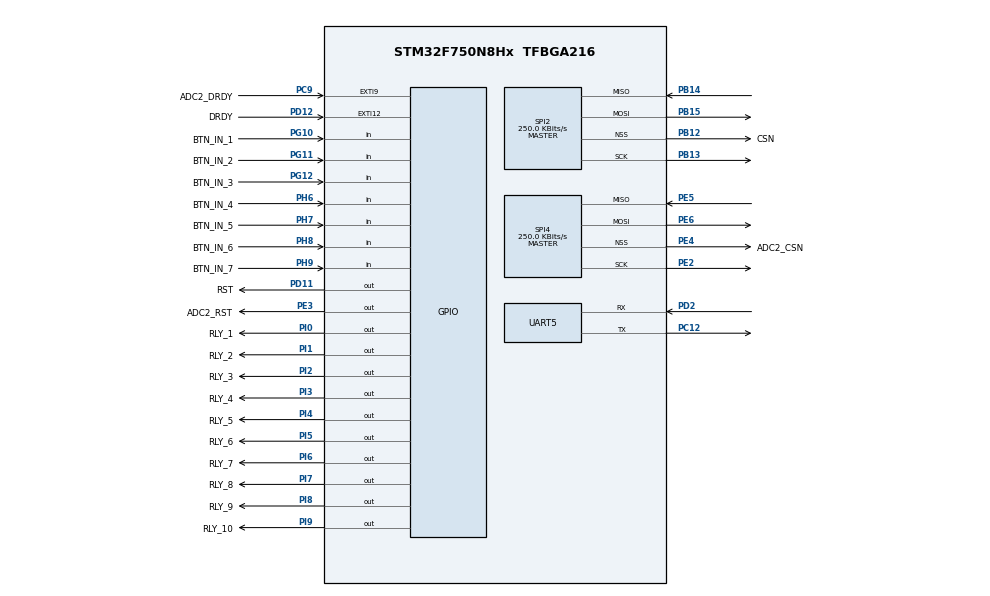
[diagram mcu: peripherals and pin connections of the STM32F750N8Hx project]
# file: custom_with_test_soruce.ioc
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FREERTOS.BinarySemaphores01=pradeep,Dynamic,NULL
FREERTOS.Tasks01=defaultTask,24,128,StartDefaultTask,Default,NULL,Dynamic,NULL,NULL;myTask02,24,128,StartTask02,Default,NULL,Dynamic,NULL,NULL
FREERTOS.configCHECK_FOR_STACK_OVERFLOW=2
FREERTOS.configUSE_IDLE_HOOK=1
FREERTOS.configUSE_MALLOC_FAILED_HOOK=1
FREERTOS.configUSE_NEWLIB_REENTRANT=1
FREERTOS.configUSE_TICK_HOOK=1
Mcu.Family=STM32F7
Mcu.Name=STM32F750N8Hx
Mcu.Package=TFBGA216
NVIC.EXTI15_10_IRQn=true\:5\:0\:false\:false\:true\:true\:true\:true\:true
NVIC.EXTI9_5_IRQn=true\:5\:0\:false\:false\:true\:true\:true\:true\:true
NVIC.PriorityGroup=NVIC_PRIORITYGROUP_4
NVIC.TIM1_UP_TIM10_IRQn=true\:5\:0\:false\:false\:true\:true\:true\:true\:true
NVIC.TIM7_IRQn=true\:15\:0\:false\:false\:true\:false\:false\:true\:true
NVIC.TimeBase=TIM7_IRQn
NVIC.TimeBaseIP=TIM7
PB12.GPIO_Label=CSN
PB12.Mode=NSS_Signal_Hard_Output
PB12.Signal=SPI2_NSS
PB13.Mode=Full_Duplex_Master
PB13.Signal=SPI2_SCK
PB14.Mode=Full_Duplex_Master
PB14.Signal=SPI2_MISO
PB15.Mode=Full_Duplex_Master
PB15.Signal=SPI2_MOSI
PC12.Mode=Asynchronous
PC12.Signal=UART5_TX
PC9.GPIO_Label=ADC2_DRDY
PC9.GPIO_ModeDefaultEXTI=GPIO_MODE_IT_FALLING
PC9.GPIO_PuPd=GPIO_PULLUP
PC9.Signal=GPXTI9
PD11.GPIO_Label=RST
PD11.Signal=GPIO_Output
PD12.GPIO_Label=DRDY
PD12.GPIO_ModeDefaultEXTI=GPIO_MODE_IT_FALLING
PD12.GPIO_PuPd=GPIO_PULLUP
PD12.Signal=GPXTI12
PD2.Mode=Asynchronous
PD2.Signal=UART5_RX
PE2.Mode=Full_Duplex_Master
PE2.Signal=SPI4_SCK
PE3.GPIO_Label=ADC2_RST
PE3.Signal=GPIO_Output
PE4.GPIO_Label=ADC2_CSN
PE4.Mode=NSS_Signal_Hard_Output
PE4.Signal=SPI4_NSS
PE5.Mode=Full_Duplex_Master
PE5.Signal=SPI4_MISO
PE6.Mode=Full_Duplex_Master
PE6.Signal=SPI4_MOSI
PG10.GPIO_Label=BTN_IN_1
PG10.Signal=GPIO_Input
PG11.GPIO_Label=BTN_IN_2
PG11.Signal=GPIO_Input
PG12.GPIO_Label=BTN_IN_3
PG12.Signal=GPIO_Input
PH0/OSC_IN.Mode=HSE-External-Oscillator
PH0/OSC_IN.Signal=RCC_OSC_IN
PH1/OSC_OUT.Mode=HSE-External-Oscillator
PH1/OSC_OUT.Signal=RCC_OSC_OUT
PH6.GPIO_Label=BTN_IN_4
PH6.Signal=GPIO_Input
PH7.GPIO_Label=BTN_IN_5
PH7.Signal=GPIO_Input
PH8.GPIO_Label=BTN_IN_6
PH8.Signal=GPIO_Input
PH9.GPIO_Label=BTN_IN_7
PH9.Signal=GPIO_Input
PI0.GPIO_Label=RLY_1
PI0.Signal=GPIO_Output
PI1.GPIO_Label=RLY_2
PI1.Signal=GPIO_Output
PI2.GPIO_Label=RLY_3
PI2.Signal=GPIO_Output
PI3.GPIO_Label=RLY_4
PI3.Signal=GPIO_Output
PI4.GPIO_Label=RLY_5
PI4.Signal=GPIO_Output
PI5.GPIO_Label=RLY_6
PI5.Signal=GPIO_Output
PI6.GPIO_Label=RLY_7
PI6.Signal=GPIO_Output
PI7.GPIO_Label=RLY_8
PI7.Signal=GPIO_Output
PI8.GPIO_Label=RLY_9
PI8.Signal=GPIO_Output
PI9.GPIO_Label=RLY_10
PI9.Signal=GPIO_Output
ProjectManager.HeapSize=0x200
ProjectManager.StackSize=0x400
ProjectManager.TargetToolchain=STM32CubeIDE
RCC.HSE_VALUE=25000000
RCC.HSI_VALUE=16000000
RCC.LSE_VALUE=32768
RCC.USBFreq_Value=96000000
RCC.VCOOutputFreq_Value=192000000
SPI2.BaudRatePrescaler=SPI_BAUDRATEPRESCALER_64
SPI2.CLKPhase=SPI_PHASE_2EDGE
SPI2.CalculateBaudRate=250.0 KBits/s
SPI2.DataSize=SPI_DATASIZE_8BIT
SPI2.Direction=SPI_DIRECTION_2LINES
SPI2.Mode=SPI_MODE_MASTER
SPI2.VirtualNSS=VM_NSSHARD
SPI2.VirtualType=VM_MASTER
SPI4.BaudRatePrescaler=SPI_BAUDRATEPRESCALER_64
SPI4.CLKPhase=SPI_PHASE_2EDGE
SPI4.CalculateBaudRate=250.0 KBits/s
SPI4.DataSize=SPI_DATASIZE_8BIT
SPI4.Direction=SPI_DIRECTION_2LINES
SPI4.Mode=SPI_MODE_MASTER
SPI4.VirtualNSS=VM_NSSHARD
SPI4.VirtualType=VM_MASTER
TIM1.Prescaler=36000-1
TIM12.Prescaler=16-1
TIM9.Prescaler=16-1
VP_FREERTOS_VS_CMSIS_V2.Mode=CMSIS_V2
VP_SYS_VS_tim7.Mode=TIM7
VP_TIM12_VS_ClockSourceINT.Mode=Internal
VP_TIM1_VS_ClockSourceINT.Mode=Internal
VP_TIM9_VS_ClockSourceINT.Mode=Internal
board=custom

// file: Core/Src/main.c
/* USER CODE BEGIN Header */
/**
  ******************************************************************************
  * @file           : main.c
  * @brief          : Main program body
  ******************************************************************************
  * @attention
  *
  * Copyright (c) 2022 STMicroelectronics.
  * All rights reserved.
  *
  * This software is licensed under terms that can be found in the LICENSE file
  * in the root directory of this software component.
  * If no LICENSE file comes with this software, it is provided AS-IS.
  *
  ******************************************************************************
  */
/* USER CODE END Header */
#include "main.h"
#include "cmsis_os.h"
#include "retarget.h"
#include "ADS1256.h"
#include "ADC_CUSTOM.h"
#include "spi.h"
#include "gpio.h"
#include "tim.h"
#include "stdio.h"
#include "string.h"

extern ads125x_channel_info_t ads125x_channel_info;
extern ads125x_conf_t ads125x_conf;
//static uint8_t is_adc_drdy,is_timer_expired;

extern ADC_CHANNEL_INFO_T ADC_CHANNEL_INFO;
extern ADC_CONFIG_T ADC_CONFIG;
//static uint8_t IS_ADC_DRDY,IS_TIMER_EXPIRED;

UART_HandleTypeDef huart5;

/* Definitions for defaultTask */
osThreadId_t defaultTaskHandle;
const osThreadAttr_t defaultTask_attributes = {
  .name = "defaultTask",
  .stack_size = 128 * 4,
  .priority = (osPriority_t) osPriorityNormal,
};
/* Definitions for myTask02 */
osThreadId_t myTask02Handle;
const osThreadAttr_t myTask02_attributes = {
  .name = "myTask02",
  .stack_size = 128 * 4,
  .priority = (osPriority_t) osPriorityNormal,
};
/* Definitions for pradeep */
osSemaphoreId_t pradeepHandle;
const osSemaphoreAttr_t pradeep_attributes = {
  .name = "pradeep"
};

void SystemClock_Config(void);
static void MX_UART5_Init(void);
void StartDefaultTask(void *argument);
void StartTask02(void *argument);

int main(void)
{

  /* MCU Configuration--------------------------------------------------------*/

  /* Reset of all peripherals, Initializes the Flash interface and the Systick. */
  HAL_Init();

  /* Configure the system clock */
  SystemClock_Config();

  /* Initialize all configured peripherals */
  MX_GPIO_Init();
  MX_SPI2_Init();
  MX_UART5_Init();
  MX_SPI4_Init();
  MX_TIM12_Init();
  MX_TIM9_Init();
  MX_TIM1_Init();
  RetargetInit(&huart5);
  hal_tim1_rpti_init(ads125x_conf.report_interval_ms);
  uint8_t status = ads1256_init();

  if(status == 1)
  {
	  printf("initialization was done for off_board\r\n");
  }
  else
  {
	  printf("initialization was not done for off_board\r\n");
  }

  status = ADC_INIT();
  if(status == 1)
  {
	  printf("initialization was done for on_board\r\n");
  }
  else
  {
	  printf("initialization was not done for on_board\r\n");
  }

  /* Init scheduler */
  osKernelInitialize();

  /* Create the semaphores(s) */
  /* creation of pradeep */
  pradeepHandle = osSemaphoreNew(1, 1, &pradeep_attributes);

  /* Create the thread(s) */
  /* creation of defaultTask */
  defaultTaskHandle = osThreadNew(StartDefaultTask, NULL, &defaultTask_attributes);

  /* creation of myTask02 */
  myTask02Handle = osThreadNew(StartTask02, NULL, &myTask02_attributes);

  /* Start scheduler */
  osKernelStart();

  /* We should never get here as control is now taken by the scheduler */
  /* Infinite loop */
  while (1)
  {

  }
}

void SystemClock_Config(void)
{
  RCC_OscInitTypeDef RCC_OscInitStruct = {0};
  RCC_ClkInitTypeDef RCC_ClkInitStruct = {0};

  /** Configure the main internal regulator output voltage
  */
  __HAL_RCC_PWR_CLK_ENABLE();
  __HAL_PWR_VOLTAGESCALING_CONFIG(PWR_REGULATOR_VOLTAGE_SCALE3);

  /** Initializes the RCC Oscillators according to the specified parameters
  * in the RCC_OscInitTypeDef structure.
  */
  RCC_OscInitStruct.OscillatorType = RCC_OSCILLATORTYPE_HSI;
  RCC_OscInitStruct.HSIState = RCC_HSI_ON;
  RCC_OscInitStruct.HSICalibrationValue = RCC_HSICALIBRATION_DEFAULT;
  RCC_OscInitStruct.PLL.PLLState = RCC_PLL_NONE;
  if (HAL_RCC_OscConfig(&RCC_OscInitStruct) != HAL_OK)
  {
    Error_Handler();
  }

  /** Initializes the CPU, AHB and APB buses clocks
  */
  RCC_ClkInitStruct.ClockType = RCC_CLOCKTYPE_HCLK|RCC_CLOCKTYPE_SYSCLK
                              |RCC_CLOCKTYPE_PCLK1|RCC_CLOCKTYPE_PCLK2;
  RCC_ClkInitStruct.SYSCLKSource = RCC_SYSCLKSOURCE_HSI;
  RCC_ClkInitStruct.AHBCLKDivider = RCC_SYSCLK_DIV1;
  RCC_ClkInitStruct.APB1CLKDivider = RCC_HCLK_DIV1;
  RCC_ClkInitStruct.APB2CLKDivider = RCC_HCLK_DIV1;

  if (HAL_RCC_ClockConfig(&RCC_ClkInitStruct, FLASH_LATENCY_0) != HAL_OK)
  {
    Error_Handler();
  }
}

static void MX_UART5_Init(void)
{

  huart5.Instance = UART5;
  huart5.Init.BaudRate = 115200;
  huart5.Init.WordLength = UART_WORDLENGTH_8B;
  huart5.Init.StopBits = UART_STOPBITS_1;
  huart5.Init.Parity = UART_PARITY_NONE;
  huart5.Init.Mode = UART_MODE_TX_RX;
  huart5.Init.HwFlowCtl = UART_HWCONTROL_NONE;
  huart5.Init.OverSampling = UART_OVERSAMPLING_16;
  huart5.Init.OneBitSampling = UART_ONE_BIT_SAMPLE_DISABLE;
  huart5.AdvancedInit.AdvFeatureInit = UART_ADVFEATURE_NO_INIT;
  if (HAL_UART_Init(&huart5) != HAL_OK)
  {
    Error_Handler();
  }

}

void StartDefaultTask(void *argument)
{
  /* USER CODE BEGIN 5 */
  /* Infinite loop */
  for(;;)
  {
//	  do
//	  {
//		  //	  	  IS_ADC_DRDY = 0;
//		  		  __disable_irq();
//		  		  ADC_DRDY_ISR();
//		  		  __enable_irq();
//	  }
//	  while(HAL_GPIO_ReadPin(DRDY_GPIO_Port, DRDY_Pin) == 0);

if(HAL_GPIO_ReadPin(DRDY_GPIO_Port, DRDY_Pin) == 0)
{

	osSemaphoreAcquire(pradeepHandle, osWaitForever);
	__disable_irq();
	ADC_DRDY_ISR();
	__enable_irq();
	 osSemaphoreRelease(pradeepHandle);
}
else
{

}

//  	  ADS1256_GetAll(ADC_Value);
//  	  float mV = (ADC_Value[0]*2*2.5)/(32 * 8388607)*1000;
//  	  printf("ADC_Value:%lf mvolts\t",mV);
//  	  float psi, res = 0.00005;
//  	  int psi_int = (0.0629*mV - 0.1306)/res;  //converting milli volts into psi
//  	  psi = psi_int*res;
//  	  printf("pis:%f\r\n",psi);

  }
  /* USER CODE END 5 */
}

void StartTask02(void *argument)
{
  /* USER CODE BEGIN StartTask02 */
  /* Infinite loop */
  for(;;)
  {

//    printf("second_task\r\n");

//    osDelay(2000);
//	    do
//		  {
//			  //is_adc_drdy = 0;
//			  __disable_irq();
//			  ads1256_drdy_isr();
//			  __enable_irq();
//
//		  }
//		  while(HAL_GPIO_ReadPin(ADC2_DRDY_GPIO_Port, ADC2_DRDY_Pin) == 0);
//	    osThreadSuspend(myTask02Handle);

	    if(HAL_GPIO_ReadPin(ADC2_DRDY_GPIO_Port, ADC2_DRDY_Pin) == 0)
	    {
	    	osSemaphoreAcquire(pradeepHandle, osWaitForever);
	    	__disable_irq();
	    	ads1256_drdy_isr();
	    	__enable_irq();
	    	 osSemaphoreRelease(pradeepHandle);
	    }
	    else
	    {

	    }

	//	  osSemaphoreAcquire(pradeepHandle, osWaitForever);
	//	  printf("acquire\r\n");
	//	  printf("release\r\n");
	//	  osSemaphoreRelease(pradeepHandle);

  }
  /* USER CODE END StartTask02 */
}

void HAL_TIM_PeriodElapsedCallback(TIM_HandleTypeDef *htim)
{
  if (htim->Instance == TIM7) {
    HAL_IncTick();
  }
}

void Error_Handler(void)
{
  __disable_irq();
  while (1)
  {
  }
}

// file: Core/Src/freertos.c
/* USER CODE BEGIN Header */
/**
  ******************************************************************************
  * File Name          : freertos.c
  * Description        : Code for freertos applications
  ******************************************************************************
  * @attention
  *
  * Copyright (c) 2022 STMicroelectronics.
  * All rights reserved.
  *
  * This software is licensed under terms that can be found in the LICENSE file
  * in the root directory of this software component.
  * If no LICENSE file comes with this software, it is provided AS-IS.
  *
  ******************************************************************************
  */
/* USER CODE END Header */

#include "FreeRTOS.h"
#include "task.h"
#include "main.h"

/* Hook prototypes */
void vApplicationIdleHook(void);
void vApplicationTickHook(void);
void vApplicationStackOverflowHook(xTaskHandle xTask, signed char *pcTaskName);
void vApplicationMallocFailedHook(void);

/* USER CODE BEGIN 2 */
void vApplicationIdleHook( void )
{
   /* vApplicationIdleHook() will only be called if configUSE_IDLE_HOOK is set
   to 1 in FreeRTOSConfig.h. It will be called on each iteration of the idle
   task. It is essential that code added to this hook function never attempts
   to block in any way (for example, call xQueueReceive() with a block time
   specified, or call vTaskDelay()). If the application makes use of the
   vTaskDelete() API function (as this demo application does) then it is also
   important that vApplicationIdleHook() is permitted to return to its calling
   function, because it is the responsibility of the idle task to clean up
   memory allocated by the kernel to any task that has since been deleted. */
}
/* USER CODE END 2 */

/* USER CODE BEGIN 3 */
void vApplicationTickHook( void )
{
   /* This function will be called by each tick interrupt if
   configUSE_TICK_HOOK is set to 1 in FreeRTOSConfig.h. User code can be
   added here, but the tick hook is called from an interrupt context, so
   code must not attempt to block, and only the interrupt safe FreeRTOS API
   functions can be used (those that end in FromISR()). */
}
/* USER CODE END 3 */

/* USER CODE BEGIN 4 */
void vApplicationStackOverflowHook(xTaskHandle xTask, signed char *pcTaskName)
{
   /* Run time stack overflow checking is performed if
   configCHECK_FOR_STACK_OVERFLOW is defined to 1 or 2. This hook function is
   called if a stack overflow is detected. */
}
/* USER CODE END 4 */

/* USER CODE BEGIN 5 */
void vApplicationMallocFailedHook(void)
{
   /* vApplicationMallocFailedHook() will only be called if
   configUSE_MALLOC_FAILED_HOOK is set to 1 in FreeRTOSConfig.h. It is a hook
   function that will get called if a call to pvPortMalloc() fails.
   pvPortMalloc() is called internally by the kernel whenever a task, queue,
   timer or semaphore is created. It is also called by various parts of the
   demo application. If heap_1.c or heap_2.c are used, then the size of the
   heap available to pvPortMalloc() is defined by configTOTAL_HEAP_SIZE in
   FreeRTOSConfig.h, and the xPortGetFreeHeapSize() API function can be used
   to query the size of free heap space that remains (although it does not
   provide information on how the remaining heap might be fragmented). */
}
/* USER CODE END 5 */
